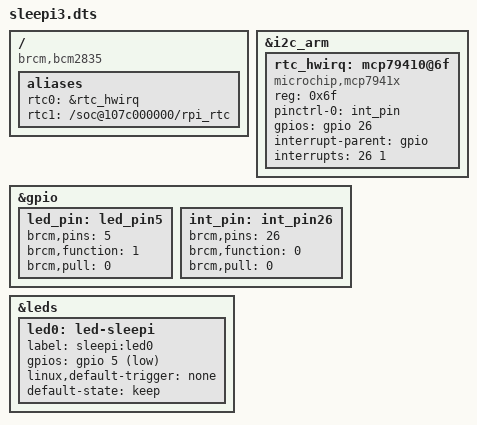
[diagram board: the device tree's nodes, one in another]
/*
 * Device Tree overlay for Mechatracks slee-Pi 3
 *
 */
/dts-v1/;
/plugin/;

/ {
	compatible = "brcm,bcm2835";

	fragment@0 {
		target = <&i2c_arm>;
		__overlay__ {
			status = "okay";
		};
	};

	fragment@1 {
		target-path="/";
		__overlay__ {
			aliases {
				rtc0 = &rtc_hwirq;
				rtc1 = "/soc@107c000000/rpi_rtc";
			};
		};
	};

	fragment@2 {
		target = <&i2c_arm>;
		__overlay__ {
			#address-cells = <1>;
			#size-cells = <0>;

			rtc_hwirq: mcp79410@6f {
				compatible = "microchip,mcp7941x";
				reg = <0x6f>;
				
				pinctrl-names = "default";
				pinctrl-0 = <&int_pin>;
				gpios = <&gpio 26 0>;
				
				interrupt-names = "irq";
				interrupt-parent = <&gpio>;
				interrupts = <26 1>;
			};
		};
	};
	
	fragment@3 {
		target-path="/";
		__dormant__ {
			aliases {
				rtc0 = &rtc_noirq;
				rtc1 = "/soc@107c000000/rpi_rtc";
			};
		};
	};

	fragment@4 {
		target = <&i2c_arm>;
		__dormant__ {
			#address-cells = <1>;
			#size-cells = <0>;

			rtc_noirq: mcp79410@6f {
				compatible = "microchip,mcp7941x";
				reg = <0x6f>;
				
				wakeup-source;
			};
		};
	};
	
	fragment@5 {
		target = <&gpio>;
		__overlay__ {
			led_pin: led_pin5 {
				brcm,pins = <5>;
				brcm,function = <1>; /* 1:out */
				brcm,pull = <0>; /* 0:none */
			};
		};
	};
	
	fragment@6 {
		target = <&gpio>;
		__overlay__ {
			int_pin: int_pin26 {
				brcm,pins = <26>;
				brcm,function = <0>; /* 0:in */
				brcm,pull = <0>; /* 0:none */
			};
		};
	};
	
	fragment@7 {
		target = <&leds>;
		__overlay__ {
			led0: led-sleepi {
				label = "sleepi:led0";
				gpios = <&gpio 5 1>;
				
				linux,default-trigger = "none";
				default-state = "keep";
			};
		};
	};
	
	fragment@8 {
		target = <&led0>;
		__dormant__ {
			linux,default-trigger = "heartbeat";
			default-state = "keep";
		};
	};
	
	__overrides__ {
		heartbeat_pin = <&led0>,"gpios:4",
				<&led_pin>,"brcm,pins:0";
		noheartbeat =   <0>,"-5-7";
		cpuheartbeat =  <0>,"+8";
		interrupt_pin = <&rtc_hwirq>,"interrupts:0",
				<&rtc_hwirq>,"gpios:4",
				<&int_pin>,"brcm,pins:0";
		nointerrupt =   <0>,"-1-2+3+4-6";
	};
};
